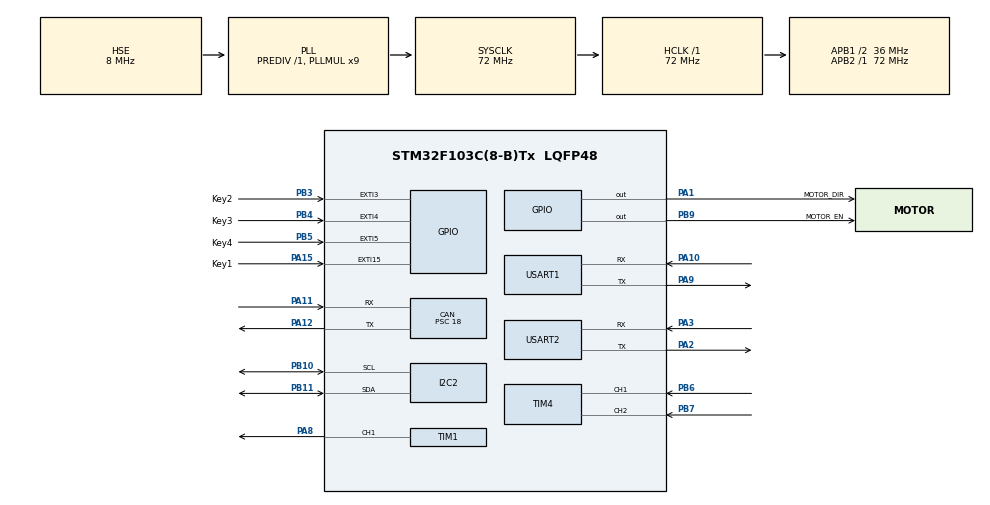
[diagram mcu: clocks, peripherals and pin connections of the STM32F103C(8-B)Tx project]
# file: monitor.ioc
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CAN.ABOM=ENABLE
CAN.AWUM=ENABLE
CAN.BS1=CAN_BS1_15TQ
CAN.BS2=CAN_BS2_4TQ
CAN.CalculateBaudRate=100000
CAN.CalculateTimeBit=10000
CAN.CalculateTimeQuantum=500.0
CAN.Mode=CAN_MODE_NORMAL
CAN.Prescaler=18
CAN.SJW=CAN_SJW_2TQ
Mcu.Family=STM32F1
Mcu.Name=STM32F103C(8-B)Tx
Mcu.Package=LQFP48
NVIC.EXTI15_10_IRQn=true\:2\:0\:true\:false\:true\:true\:true\:true
NVIC.EXTI3_IRQn=true\:2\:0\:true\:false\:true\:true\:true\:true
NVIC.EXTI4_IRQn=true\:2\:0\:true\:false\:true\:true\:true\:true
NVIC.EXTI9_5_IRQn=true\:2\:0\:true\:false\:true\:true\:true\:true
NVIC.PriorityGroup=NVIC_PRIORITYGROUP_4
NVIC.TIM1_CC_IRQn=true\:0\:0\:true\:false\:true\:true\:true\:true
NVIC.TIM2_IRQn=true\:0\:0\:false\:false\:false\:true\:true\:true
NVIC.TIM4_IRQn=true\:0\:0\:false\:false\:true\:true\:true\:true
NVIC.USART2_IRQn=true\:0\:0\:false\:false\:false\:true\:true\:true
PA1.GPIO_Label=MOTOR_DIR
PA1.GPIO_Speed=GPIO_SPEED_FREQ_HIGH
PA1.PinState=GPIO_PIN_SET
PA1.Signal=GPIO_Output
PA10.Mode=Asynchronous
PA10.Signal=USART1_RX
PA11.Mode=CAN_Activate
PA11.Signal=CAN_RX
PA12.Mode=CAN_Activate
PA12.Signal=CAN_TX
PA13.Mode=Serial_Wire
PA13.Signal=SYS_JTMS-SWDIO
PA14.Mode=Serial_Wire
PA14.Signal=SYS_JTCK-SWCLK
PA15.GPIO_Label=Key1
PA15.GPIO_ModeDefaultEXTI=GPIO_MODE_IT_FALLING
PA15.GPIO_PuPd=GPIO_PULLUP
PA15.Signal=GPXTI15
PA2.Mode=Asynchronous
PA2.Signal=USART2_TX
PA3.Mode=Asynchronous
PA3.Signal=USART2_RX
PA8.Signal=S_TIM1_CH1
PA9.Mode=Asynchronous
PA9.Signal=USART1_TX
PB10.Mode=I2C
PB10.Signal=I2C2_SCL
PB11.Mode=I2C
PB11.Signal=I2C2_SDA
PB3.GPIO_Label=Key2
PB3.GPIO_ModeDefaultEXTI=GPIO_MODE_IT_FALLING
PB3.GPIO_PuPd=GPIO_PULLUP
PB3.Signal=GPXTI3
PB4.GPIO_Label=Key3
PB4.GPIO_ModeDefaultEXTI=GPIO_MODE_IT_FALLING
PB4.GPIO_PuPd=GPIO_PULLUP
PB4.Signal=GPXTI4
PB5.GPIO_Label=Key4
PB5.GPIO_ModeDefaultEXTI=GPIO_MODE_IT_FALLING
PB5.GPIO_PuPd=GPIO_PULLUP
PB5.Signal=GPXTI5
PB6.Signal=S_TIM4_CH1
PB7.Signal=S_TIM4_CH2
PB9.GPIO_Label=MOTOR_EN
PB9.GPIO_Speed=GPIO_SPEED_FREQ_HIGH
PB9.Signal=GPIO_Output
PC14-OSC32_IN.Mode=LSE-External-Oscillator
PC14-OSC32_IN.Signal=RCC_OSC32_IN
PC15-OSC32_OUT.Mode=LSE-External-Oscillator
PC15-OSC32_OUT.Signal=RCC_OSC32_OUT
PD0-OSC_IN.Mode=HSE-External-Oscillator
PD0-OSC_IN.Signal=RCC_OSC_IN
PD1-OSC_OUT.Mode=HSE-External-Oscillator
PD1-OSC_OUT.Signal=RCC_OSC_OUT
ProjectManager.HeapSize=0x800
ProjectManager.StackSize=0x800
ProjectManager.TargetToolchain=MDK-ARM V5.32
RCC.AHBFreq_Value=72000000
RCC.APB1CLKDivider=RCC_HCLK_DIV2
RCC.APB1Freq_Value=36000000
RCC.APB1TimFreq_Value=72000000
RCC.APB2Freq_Value=72000000
RCC.APB2TimFreq_Value=72000000
RCC.HCLKFreq_Value=72000000
RCC.PLLMUL=RCC_PLL_MUL9
RCC.PLLSourceVirtual=RCC_PLLSOURCE_HSE
RCC.SYSCLKFreq_VALUE=72000000
RCC.SYSCLKSource=RCC_SYSCLKSOURCE_PLLCLK
RCC.USBFreq_Value=72000000
SH.S_TIM1_CH1.0=TIM1_CH1,Output Compare1 CH1
SH.S_TIM4_CH1.0=TIM4_CH1,Encoder_Interface
SH.S_TIM4_CH2.0=TIM4_CH2,Encoder_Interface
TIM1.AutoReloadPreload=TIM_AUTORELOAD_PRELOAD_DISABLE
TIM1.Channel-Output\ Compare1\ CH1=TIM_CHANNEL_1
TIM1.OCMode_1=TIM_OCMODE_TOGGLE
TIM1.Period=65535
TIM1.Prescaler=71
TIM2.Period=34
TIM2.Prescaler=3599
TIM3.Period=50000
TIM3.Prescaler=71
TIM4.EncoderMode=TIM_ENCODERMODE_TI12
TIM4.IC1Filter=10
TIM4.IC2Filter=10
USART1.VirtualMode=VM_ASYNC
USART2.VirtualMode=VM_ASYNC
VP_TIM1_VS_ClockSourceINT.Mode=Internal
VP_TIM2_VS_ClockSourceINT.Mode=Internal
VP_TIM3_VS_ClockSourceINT.Mode=Internal
board=custom

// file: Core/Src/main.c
/* USER CODE BEGIN Header */
/**
 ******************************************************************************
 * @file           : main.c
 * @brief          : Main program body
 ******************************************************************************
 * @attention
 *
 * Copyright (c) 2025 STMicroelectronics.
 * All rights reserved.
 *
 * This software is licensed under terms that can be found in the LICENSE file
 * in the root directory of this software component.
 * If no LICENSE file comes with this software, it is provided AS-IS.
 *
 ******************************************************************************
 */
/* USER CODE END Header */
#include "main.h"
#include "can.h"
#include "i2c.h"
#include "tim.h"
#include "usart.h"
#include "gpio.h"

/* USER CODE BEGIN Includes */
#include <stdio.h>
#include "App_Display.h"
#include "App_ModbusID.h"
#include "mb.h"
#include "App_Can.h"
/* USER CODE END Includes */

void SystemClock_Config(void);

int main(void)
{

  /* MCU Configuration--------------------------------------------------------*/

  /* Reset of all peripherals, Initializes the Flash interface and the Systick. */
  HAL_Init();

  /* Configure the system clock */
  SystemClock_Config();

  /* Initialize all configured peripherals */
  MX_GPIO_Init();
  MX_USART1_UART_Init();
  MX_I2C2_Init();
  MX_TIM1_Init();
  MX_TIM4_Init();
  MX_TIM3_Init();
  MX_USART2_UART_Init();
  MX_TIM2_Init();
  MX_CAN_Init();
  /* USER CODE BEGIN 2 */
  printf("=============Motor===============\r\n");
  // App_MosBusID_Init();

  // Can初始化
  App_Can_init();
  App_Display_Init();
  // //modbus协议初始化
  // eMBInit(MB_RTU,0x05,0,115200,MB_PAR_NONE);
  // eMBEnable();
  // printf("modbus init success\r\n");
  printf("can init success\r\n");
  /* USER CODE END 2 */

  /* Infinite loop */
  while (1)
  {

    /* USER CODE BEGIN 3 */
    App_Display_ShowPage();
    HAL_Delay(50);
    // //每隔50ms，判断一次主设备是否发过来命令
    // eMBPoll();

    // 每隔50ms,使用Can接收网关发过来的消息
    App_Can_Poll();
  }
  /* USER CODE END 3 */
}

void SystemClock_Config(void)
{
  RCC_OscInitTypeDef RCC_OscInitStruct = {0};
  RCC_ClkInitTypeDef RCC_ClkInitStruct = {0};

  /** Initializes the RCC Oscillators according to the specified parameters
   * in the RCC_OscInitTypeDef structure.
   */
  RCC_OscInitStruct.OscillatorType = RCC_OSCILLATORTYPE_HSE;
  RCC_OscInitStruct.HSEState = RCC_HSE_ON;
  RCC_OscInitStruct.HSEPredivValue = RCC_HSE_PREDIV_DIV1;
  RCC_OscInitStruct.HSIState = RCC_HSI_ON;
  RCC_OscInitStruct.PLL.PLLState = RCC_PLL_ON;
  RCC_OscInitStruct.PLL.PLLSource = RCC_PLLSOURCE_HSE;
  RCC_OscInitStruct.PLL.PLLMUL = RCC_PLL_MUL9;
  if (HAL_RCC_OscConfig(&RCC_OscInitStruct) != HAL_OK)
  {
    Error_Handler();
  }

  /** Initializes the CPU, AHB and APB buses clocks
   */
  RCC_ClkInitStruct.ClockType = RCC_CLOCKTYPE_HCLK | RCC_CLOCKTYPE_SYSCLK | RCC_CLOCKTYPE_PCLK1 | RCC_CLOCKTYPE_PCLK2;
  RCC_ClkInitStruct.SYSCLKSource = RCC_SYSCLKSOURCE_PLLCLK;
  RCC_ClkInitStruct.AHBCLKDivider = RCC_SYSCLK_DIV1;
  RCC_ClkInitStruct.APB1CLKDivider = RCC_HCLK_DIV2;
  RCC_ClkInitStruct.APB2CLKDivider = RCC_HCLK_DIV1;

  if (HAL_RCC_ClockConfig(&RCC_ClkInitStruct, FLASH_LATENCY_2) != HAL_OK)
  {
    Error_Handler();
  }
}

/* USER CODE BEGIN 4 */
// int fputc(int ch, FILE *file)
// {
//   HAL_UART_Transmit(&huart1, (uint8_t *)&ch, 1, 1000);
//   return ch;
// }
/* USER CODE END 4 */

void Error_Handler(void)
{
  __disable_irq();
  while (1)
  {
  }
}
